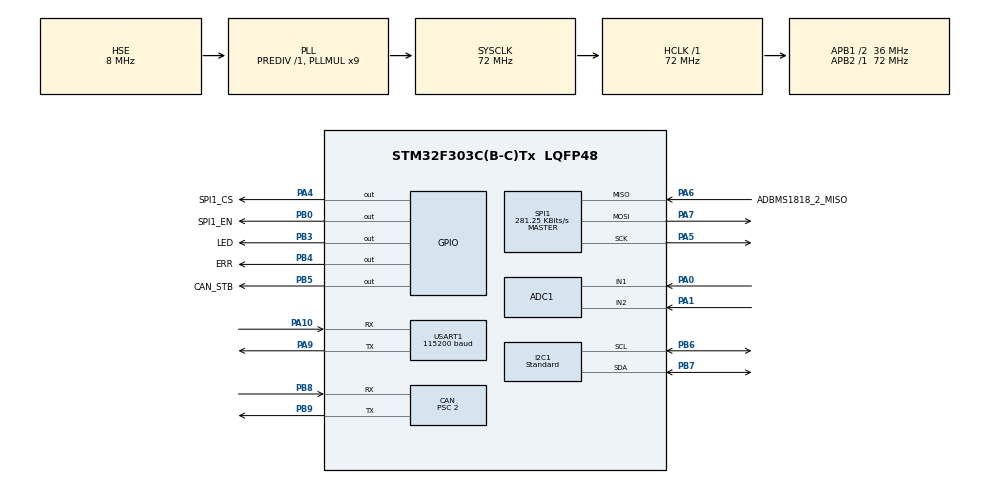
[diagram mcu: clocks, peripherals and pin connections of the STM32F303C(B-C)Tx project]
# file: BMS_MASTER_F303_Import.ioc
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ADC1.Channel-1\#ChannelRegularConversion=ADC_CHANNEL_2
ADC1.ClockPrescaler=ADC_CLOCK_SYNC_PCLK_DIV4
ADC1.ContinuousConvMode=ENABLE
ADC1.DMAContinuousRequests=ENABLE
ADC1.DataAlign=ADC_DATAALIGN_RIGHT
ADC1.DiscontinuousConvMode=DISABLE
ADC1.EnableInjectedConversion=DISABLE
ADC1.EnableRegularConversion=ENABLE
ADC1.ExternalTrigConv=ADC_SOFTWARE_START
ADC1.NbrOfConversion=2
ADC1.Rank-0\#ChannelRegularConversion=1
ADC1.Rank-1\#ChannelRegularConversion=2
ADC1.SamplingTime-0\#ChannelRegularConversion=ADC_SAMPLETIME_601CYCLES_5
ADC1.SamplingTime-1\#ChannelRegularConversion=ADC_SAMPLETIME_601CYCLES_5
ADC1.ScanConvMode=ADC_SCAN_ENABLE
ADC1.master=1
CAN.ABOM=ENABLE
CAN.AWUM=DISABLE
CAN.BS1=CAN_BS1_13TQ
CAN.BS2=CAN_BS2_4TQ
CAN.CalculateBaudRate=1000000
CAN.CalculateTimeBit=1000
CAN.CalculateTimeQuantum=55.55555555555556
CAN.Mode=CAN_MODE_NORMAL
CAN.NART=DISABLE
CAN.Prescaler=2
CAN.RFLM=DISABLE
CAN.SJW=CAN_SJW_1TQ
CAN.TTCM=DISABLE
CAN.TXFP=DISABLE
Dma.ADC1.0.Direction=DMA_PERIPH_TO_MEMORY
Dma.ADC1.0.Instance=DMA1_Channel1
Dma.ADC1.0.MemDataAlignment=DMA_MDATAALIGN_HALFWORD
Dma.ADC1.0.MemInc=DMA_MINC_ENABLE
Dma.ADC1.0.Mode=DMA_CIRCULAR
Dma.ADC1.0.PeriphDataAlignment=DMA_PDATAALIGN_HALFWORD
Dma.ADC1.0.PeriphInc=DMA_PINC_DISABLE
Dma.ADC1.0.Priority=DMA_PRIORITY_LOW
Dma.Request0=ADC1
I2C1.AddressingMode=I2C_ADDRESSINGMODE_7BIT
I2C1.DualAddressMode=I2C_DUALADDRESS_DISABLE
I2C1.GeneralCallMode=I2C_GENERALCALL_DISABLE
I2C1.I2C_Speed_Mode=I2C_Standard
I2C1.NoStretchMode=I2C_NOSTRETCH_DISABLE
I2C1.OwnAddress=0
I2C1.Speed=100
I2C1.Timing=0x00201D2B
Mcu.Family=STM32F3
Mcu.Name=STM32F303C(B-C)Tx
Mcu.Package=LQFP48
NVIC.ADC1_2_IRQn=true\:0\:0\:false\:false\:true\:true\:true\:true
NVIC.DMA1_Channel1_IRQn=true\:0\:0\:false\:false\:true\:false\:true\:true
NVIC.PriorityGroup=NVIC_PRIORITYGROUP_4
NVIC.TIM3_IRQn=true\:0\:0\:false\:false\:true\:true\:true\:true
NVIC.USB_LP_CAN_RX0_IRQn=true\:0\:0\:false\:false\:true\:false\:true\:true
PA0.Mode=IN1-Single-Ended
PA0.Signal=ADC1_IN1
PA1.Mode=IN2-Single-Ended
PA1.Signal=ADC1_IN2
PA10.Mode=Asynchronous
PA10.Signal=USART1_RX
PA13.Mode=Serial_Wire
PA13.Signal=SYS_JTMS-SWDIO
PA14.Mode=Serial_Wire
PA14.Signal=SYS_JTCK-SWCLK
PA4.GPIO_Label=SPI1_CS
PA4.Signal=GPIO_Output
PA5.Mode=Full_Duplex_Master
PA5.Signal=SPI1_SCK
PA6.GPIO_Label=ADBMS1818_2_MISO
PA6.GPIO_PuPd=GPIO_NOPULL
PA6.Mode=Full_Duplex_Master
PA6.Signal=SPI1_MISO
PA7.GPIO_PuPd=GPIO_NOPULL
PA7.Mode=Full_Duplex_Master
PA7.Signal=SPI1_MOSI
PA9.Mode=Asynchronous
PA9.Signal=USART1_TX
PB0.GPIO_Label=SPI1_EN
PB0.GPIO_PuPd=GPIO_NOPULL
PB0.Signal=GPIO_Output
PB3.GPIO_Label=LED
PB3.Signal=GPIO_Output
PB4.GPIO_Label=ERR
PB4.Signal=GPIO_Output
PB5.GPIO_Label=CAN_STB
PB5.GPIO_PuPd=GPIO_NOPULL
PB5.Signal=GPIO_Output
PB6.Mode=I2C
PB6.Signal=I2C1_SCL
PB7.Mode=I2C
PB7.Signal=I2C1_SDA
PB8.Mode=CAN_Activate
PB8.Signal=CAN_RX
PB9.Mode=CAN_Activate
PB9.Signal=CAN_TX
PF0-OSC_IN.Mode=HSE-External-Oscillator
PF0-OSC_IN.Signal=RCC_OSC_IN
PF1-OSC_OUT.Mode=HSE-External-Oscillator
PF1-OSC_OUT.Signal=RCC_OSC_OUT
ProjectManager.HeapSize=0x200
ProjectManager.StackSize=0x400
ProjectManager.TargetToolchain=Makefile
RCC.AHBFreq_Value=72000000
RCC.APB1CLKDivider=RCC_HCLK_DIV2
RCC.APB1Freq_Value=36000000
RCC.APB1TimFreq_Value=72000000
RCC.APB2Freq_Value=72000000
RCC.APB2TimFreq_Value=72000000
RCC.CortexFreq_Value=72000000
RCC.FLatency=FLASH_LATENCY_2
RCC.HCLKFreq_Value=72000000
RCC.HSE_VALUE=8000000
RCC.HSI_VALUE=8000000
RCC.LSE_VALUE=32768
RCC.PLLMUL=RCC_PLL_MUL9
RCC.PLLSourceVirtual=RCC_PLLSOURCE_HSE
RCC.PRESCALERUSB=RCC_USBCLKSOURCE_PLL_DIV1_5
RCC.SYSCLKFreq_VALUE=72000000
RCC.SYSCLKSourceVirtual=RCC_SYSCLKSOURCE_PLLCLK
RCC.USBFreq_Value=48000000
SPI1.BaudRatePrescaler=SPI_BAUDRATEPRESCALER_256
SPI1.CLKPhase=SPI_PHASE_2EDGE
SPI1.CLKPolarity=SPI_POLARITY_HIGH
SPI1.CRCCalculation=SPI_CRCCALCULATION_DISABLE
SPI1.CalculateBaudRate=281.25 KBits/s
SPI1.DataSize=SPI_DATASIZE_8BIT
SPI1.Direction=SPI_DIRECTION_2LINES
SPI1.FirstBit=SPI_FIRSTBIT_MSB
SPI1.Mode=SPI_MODE_MASTER
SPI1.NSS=SPI_NSS_SOFT
SPI1.TIMode=SPI_TIMODE_DISABLE
SPI1.VirtualType=VM_MASTER
TIM3.AutoReloadPreload=TIM_AUTORELOAD_PRELOAD_DISABLE
TIM3.ClockDivision=TIM_CLOCKDIVISION_DIV1
TIM3.CounterMode=TIM_COUNTERMODE_UP
TIM3.Period=500-1
TIM3.Prescaler=36000-1
TIM3.TIM_MasterOutputTrigger=TIM_TRGO_RESET
TIM3.TIM_MasterSlaveMode=TIM_MASTERSLAVEMODE_DISABLE
USART1.BaudRate=115200
USART1.Mode=MODE_TX_RX
USART1.Parity=PARITY_NONE
USART1.StopBits=STOPBITS_1
USART1.VirtualMode-Asynchronous=VM_ASYNC
USART1.WordLength=WORDLENGTH_8B
VP_TIM3_VS_ClockSourceINT.Mode=Internal
board=custom

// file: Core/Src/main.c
/* USER CODE BEGIN Header */
/**
  ******************************************************************************
  * @file           : main.c
  * @brief          : Main program body
  ******************************************************************************
  * @attention
  *
  * Copyright (c) 2024 STMicroelectronics.
  * All rights reserved.
  *
  * This software is licensed under terms that can be found in the LICENSE file
  * in the root directory of this software component.
  * If no LICENSE file comes with this software, it is provided AS-IS.
  *
  ******************************************************************************
  */
/* USER CODE END Header */
#include "main.h"
#include "adc.h"
#include "can.h"
#include "dma.h"
#include "i2c.h"
#include "spi.h"
#include "tim.h"
#include "usart.h"
#include "usb_device.h"
#include "gpio.h"

void SystemClock_Config(void);
/* USER CODE BEGIN PFP */
extern void init();
extern volatile void loop();
/* USER CODE END PFP */

int main(void)
{

  /* MCU Configuration--------------------------------------------------------*/

  /* Reset of all peripherals, Initializes the Flash interface and the Systick. */
  HAL_Init();

  /* Configure the system clock */
  SystemClock_Config();

  /* Initialize all configured peripherals */
  MX_GPIO_Init();
  MX_DMA_Init();
  MX_SPI1_Init();
  MX_ADC1_Init();
  MX_CAN_Init();
  MX_I2C1_Init();
  MX_USART1_UART_Init();
  MX_TIM3_Init();
  MX_USB_DEVICE_Init();
  /* USER CODE BEGIN 2 */

  init();
  /* USER CODE END 2 */

  /* Infinite loop */
  while (1)
  {

    /* USER CODE BEGIN 3 */
    loop();
  }
  /* USER CODE END 3 */
}

void SystemClock_Config(void)
{
  RCC_OscInitTypeDef RCC_OscInitStruct = {0};
  RCC_ClkInitTypeDef RCC_ClkInitStruct = {0};
  RCC_PeriphCLKInitTypeDef PeriphClkInit = {0};

  /** Initializes the RCC Oscillators according to the specified parameters
  * in the RCC_OscInitTypeDef structure.
  */
  RCC_OscInitStruct.OscillatorType = RCC_OSCILLATORTYPE_HSI|RCC_OSCILLATORTYPE_HSE;
  RCC_OscInitStruct.HSEState = RCC_HSE_ON;
  RCC_OscInitStruct.HSEPredivValue = RCC_HSE_PREDIV_DIV1;
  RCC_OscInitStruct.HSIState = RCC_HSI_ON;
  RCC_OscInitStruct.HSICalibrationValue = RCC_HSICALIBRATION_DEFAULT;
  RCC_OscInitStruct.PLL.PLLState = RCC_PLL_ON;
  RCC_OscInitStruct.PLL.PLLSource = RCC_PLLSOURCE_HSE;
  RCC_OscInitStruct.PLL.PLLMUL = RCC_PLL_MUL9;
  if (HAL_RCC_OscConfig(&RCC_OscInitStruct) != HAL_OK)
  {
    Error_Handler();
  }

  /** Initializes the CPU, AHB and APB buses clocks
  */
  RCC_ClkInitStruct.ClockType = RCC_CLOCKTYPE_HCLK|RCC_CLOCKTYPE_SYSCLK
                              |RCC_CLOCKTYPE_PCLK1|RCC_CLOCKTYPE_PCLK2;
  RCC_ClkInitStruct.SYSCLKSource = RCC_SYSCLKSOURCE_PLLCLK;
  RCC_ClkInitStruct.AHBCLKDivider = RCC_SYSCLK_DIV1;
  RCC_ClkInitStruct.APB1CLKDivider = RCC_HCLK_DIV2;
  RCC_ClkInitStruct.APB2CLKDivider = RCC_HCLK_DIV1;

  if (HAL_RCC_ClockConfig(&RCC_ClkInitStruct, FLASH_LATENCY_2) != HAL_OK)
  {
    Error_Handler();
  }
  PeriphClkInit.PeriphClockSelection = RCC_PERIPHCLK_USB|RCC_PERIPHCLK_USART1
                              |RCC_PERIPHCLK_I2C1;
  PeriphClkInit.Usart1ClockSelection = RCC_USART1CLKSOURCE_PCLK2;
  PeriphClkInit.I2c1ClockSelection = RCC_I2C1CLKSOURCE_HSI;
  PeriphClkInit.USBClockSelection = RCC_USBCLKSOURCE_PLL_DIV1_5;
  if (HAL_RCCEx_PeriphCLKConfig(&PeriphClkInit) != HAL_OK)
  {
    Error_Handler();
  }
}

void Error_Handler(void)
{
  __disable_irq();
  while (1)
  {
  }
}
